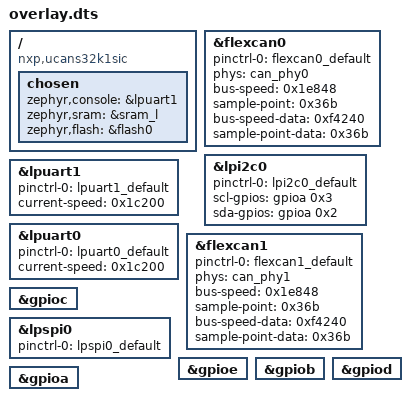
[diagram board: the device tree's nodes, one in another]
/ {
	compatible = "nxp,ucans32k1sic";
	chosen {
		zephyr,console = &lpuart1;
		zephyr,sram = &sram_l;
		zephyr,flash = &flash0;
	};
};
&flexcan0{
	status = "okay";
	pinctrl-0 = < &flexcan0_default >;
	pinctrl-names = "default";
	phys = < &can_phy0 >;
	bus-speed = < 0x1e848 >;
	sample-point = < 0x36b >;
	bus-speed-data = < 0xf4240 >;
	sample-point-data = < 0x36b >;
};
&lpi2c0{
	status = "okay";
	pinctrl-0 = < &lpi2c0_default >;
	pinctrl-names = "default";
	scl-gpios = < &gpioa 0x3 0x0 >;
	sda-gpios = < &gpioa 0x2 0x0 >;
};
&lpuart1{
	status = "okay";
	pinctrl-0 = < &lpuart1_default >;
	pinctrl-names = "default";
	current-speed = < 0x1c200 >;
};
&lpuart0{
	pinctrl-0 = < &lpuart0_default >;
	pinctrl-names = "default";
	current-speed = < 0x1c200 >;
};
&flexcan1{
	status = "okay";
	pinctrl-0 = < &flexcan1_default >;
	pinctrl-names = "default";
	phys = < &can_phy1 >;
	bus-speed = < 0x1e848 >;
	sample-point = < 0x36b >;
	bus-speed-data = < 0xf4240 >;
	sample-point-data = < 0x36b >;
};
&gpioc{
	status = "okay";
};
&lpspi0{
	status = "okay";
	pinctrl-0 = < &lpspi0_default >;
	pinctrl-names = "default";
};
&gpioe{
	status = "okay";
};
&gpiob{
	status = "okay";
};
&gpiod{
	status = "okay";
};
&gpioa{
	status = "okay";
};
